VERSION "DBC_PCAN_THERMOCOUPLE"

NS_ :

BS_:

BU_:

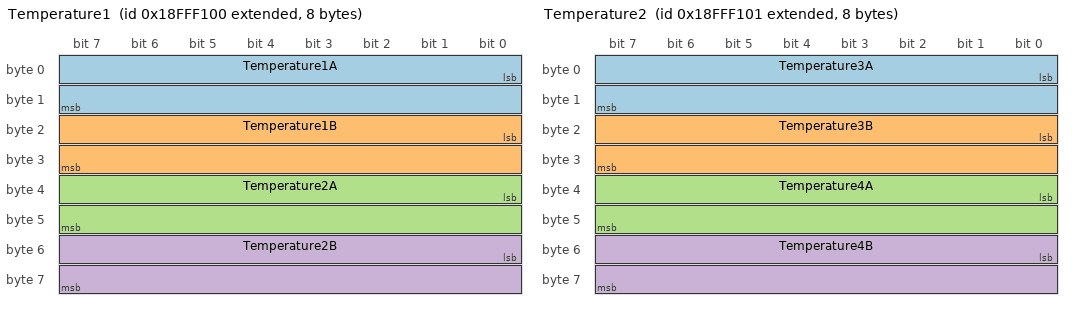
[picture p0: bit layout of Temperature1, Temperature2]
BO_ 2566910208 Temperature1: 8 Vector__XXX
	SG_ Temperature1A : 0|16@1- (0.0625,0) [0|0] "" Vector__XXX
	SG_ Temperature1B : 16|16@1- (0.0625,0) [0|0] "" Vector__XXX
	SG_ Temperature2A : 32|16@1- (0.0625,0) [0|0] "" Vector__XXX
	SG_ Temperature2B : 48|16@1- (0.0625,0) [0|0] "" Vector__XXX

BO_ 2566910209 Temperature2: 8 Vector__XXX
	SG_ Temperature3A : 0|16@1- (0.0625,0) [0|0] "" Vector__XXX
	SG_ Temperature3B : 16|16@1- (0.0625,0) [0|0] "" Vector__XXX
	SG_ Temperature4A : 32|16@1- (0.0625,0) [0|0] "" Vector__XXX
	SG_ Temperature4B : 48|16@1- (0.0625,0) [0|0] "" Vector__XXX

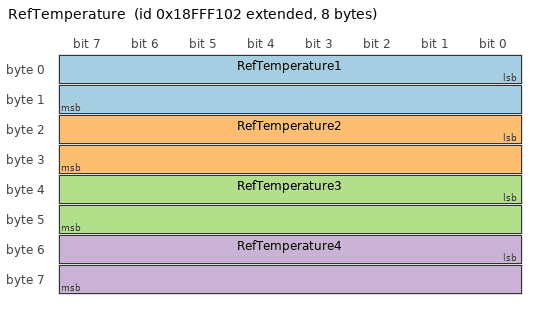
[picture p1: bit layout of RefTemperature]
BO_ 2566910210 RefTemperature: 8 Vector__XXX
	SG_ RefTemperature1 : 0|16@1- (0.0625,0) [0|0] "" Vector__XXX
	SG_ RefTemperature2 : 16|16@1- (0.0625,0) [0|0] "" Vector__XXX
	SG_ RefTemperature3 : 32|16@1- (0.0625,0) [0|0] "" Vector__XXX
	SG_ RefTemperature4 : 48|16@1- (0.0625,0) [0|0] "" Vector__XXX

BA_DEF_ SG_  "SPN" INT 0 524287;
BA_DEF_ BO_  "VFrameFormat" ENUM  "StandardCAN","ExtendedCAN","reserved","J1939PG";
BA_DEF_  "DatabaseVersion" STRING ;
BA_DEF_  "BusType" STRING ;
BA_DEF_  "ProtocolType" STRING ;
BA_DEF_  "DatabaseCompiler" STRING ;
BA_DEF_DEF_  "SPN" 0;
BA_DEF_DEF_  "VFrameFormat" "J1939PG";
BA_DEF_DEF_  "DatabaseVersion" "DEMO PLUS";
BA_DEF_DEF_  "BusType" "";
BA_DEF_DEF_  "ProtocolType" "";
BA_DEF_DEF_  "DatabaseCompiler" "";
BA_ "ProtocolType" "J1939";
BA_ "BusType" "CAN";
BA_ "DatabaseCompiler" "CSS ELECTRONICS (WWW.CSSELECTRONICS.COM)";
BA_ "DatabaseVersion" "1.0.0";
BA_ "SPN" SG_ 2364540158 EngineSpeed 190;
